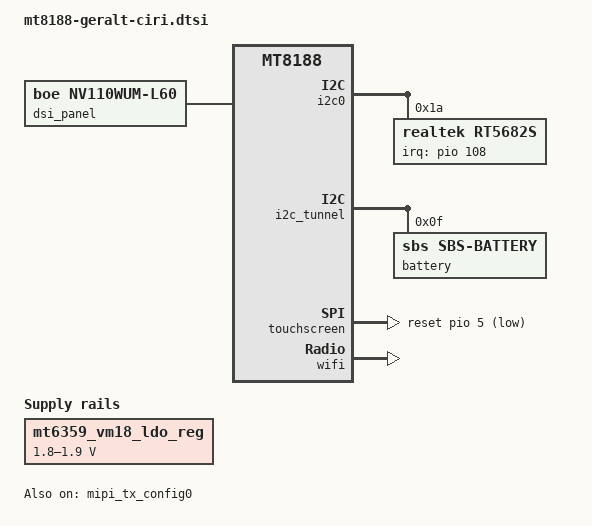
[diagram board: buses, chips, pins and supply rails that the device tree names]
// SPDX-License-Identifier: (GPL-2.0 OR MIT)
/*
 * Copyright 2023 Google LLC
 */
/dts-v1/;
#include "mt8188-geralt.dtsi"

/delete-node/ &dp_intf0;
/delete-node/ &edp_panel;
/delete-node/ &edp_tx;
/delete-node/ &max98390_3a;
/delete-node/ &max98390_3b;
/delete-node/ &nau8825;
/delete-node/ &pp3300_edp_disp;

&aud_etdm_spk_on {
	pins-bus {
		drive-strength = <MTK_DRIVE_8mA>;
	};
};

&dsi_panel {
	compatible = "boe,nv110wum-l60";
};

&disp_pwm1 {
	status = "disabled";
};

&dmic_codec {
	wakeup-delay-ms = <100>;
};

&i2c0 {
	rt5682s: rt5682s@1a {
		compatible = "realtek,rt5682s";
		reg = <0x1a>;
		interrupt-parent = <&pio>;
		interrupts = <108 IRQ_TYPE_EDGE_BOTH>;
		realtek,jd-src = <1>;
		#sound-dai-cells = <0>;
		status = "okay";
	};
};

&max98390_38 {
	sound-name-prefix = "Front Right";
	maxim,dsm_param_name = "dsm_param.bin";
};

&max98390_39 {
	sound-name-prefix = "Front Left";
	maxim,dsm_param_name = "dsm_param.bin";
};

&mipi_tx_config0 {
	drive-strength-microamp = <5200>;
	status = "okay";
};

&mt6359_vm18_ldo_reg {
	regulator-min-microvolt = <1800000>;
	regulator-microvolt-offset = <100000>;
	regulator-max-microvolt = <1900000>;
};

&i2c_tunnel {
	/delete-node/ sbs-battery@b;

	battery: sbs-battery@f {
		compatible = "sbs,sbs-battery";
		reg = <0xf>;
		sbs,i2c-retry-count = <2>;
		sbs,poll-retry-count = <1>;
	};
};

&i2c2 {
	status = "disabled";
};

&mmc1 {
	status = "disabled";
};

&ap_sar_sensor {
	status = "disabled";
};

&sound {
	compatible = "mediatek,mt8188-rt5682s";
	model = "mt8188_m98390_5682";

	audio-routing =
		"ETDM1_OUT", "ETDM_SPK_PIN",
		"ETDM2_OUT", "ETDM_HP_PIN",
		"ETDM1_IN", "ETDM_SPK_PIN",
		"ETDM2_IN", "ETDM_HP_PIN",
		"ADDA Capture", "MTKAIF_PIN",
		"Headphone Jack", "HPOL",
		"Headphone Jack", "HPOR",
		"IN1P", "Headset Mic",
		"Left Spk", "Front Left BE_OUT",
		"Right Spk", "Front Right BE_OUT";
	status = "okay";

	dai-link-0 {
		link-name = "ETDM2_OUT_BE";
		mediatek,clk-provider = "cpu";

		codec {
			sound-dai = <&rt5682s>;
		};
	};

	dai-link-1 {
		link-name = "ETDM2_IN_BE";
		mediatek,clk-provider = "cpu";

		codec {
			sound-dai = <&rt5682s>;
		};
	};

	dai-link-2 {
		link-name = "ETDM1_OUT_BE";
		dai-format = "i2s";
		mediatek,clk-provider = "cpu";

		codec {
			sound-dai = <&max98390_38>,
				    <&max98390_39>;
		};
	};

	dai-link-3 {
		link-name = "ETDM1_IN_BE";
		dai-format = "i2s";
		mediatek,clk-provider = "cpu";
	};
};

&spi1 {
	#address-cells = <1>;
	#size-cells = <0>;
	num-cs = <1>;
	pinctrl-names = "default", "sleep";
	pinctrl-0 = <&spi1_default>;
	pinctrl-1 = <&spi1_sleep>;

	touchscreen: hid-hx-common-spi@0 {
		compatible = "himax,hx83102j";
		reg = <0>;
		firmware-name = "himax_i2chid_1002.bin";
		interrupt-parent = <&pio>;
		interrupts = <143 IRQ_TYPE_LEVEL_LOW>;
		irq_flag = <0x02>;
		panel = <&dsi_panel>;
		pinctrl-names = "default";
		pinctrl-0 = <&tchscr_int &tchscr_rst>;
		reset-gpios = <&pio 5 GPIO_ACTIVE_LOW>;
		spi-max-frequency = <12500000>;
		himax_gpio_irq = <&pio 143 IRQ_TYPE_LEVEL_LOW>;
		himax,pid = <0x1002>;
		status = "okay";
	};
};

&thermal_zones {
	soc_max {
		trips {
			target: target@1 {
				temperature = <90000>;
				hysteresis = <2000>;
				type = "passive";
			};
		};
	};
};

&aud_etdm_hp_on {
	pins-mclk {
		pinmux = <PINMUX_GPIO114__FUNC_O_I2SO2_MCK>;
	};
};

&aud_etdm_hp_off {
	pins-mclk {
		pinmux = <PINMUX_GPIO114__FUNC_B_GPIO114>;
		bias-pull-down;
		input-enable;
	};
};

&pio {
	gpio-line-names =
		"GSC_AP_INT_ODL",
		"AP_DISP_BKLTEN",
		"",
		"EN_PPVAR_MIPI_DISP",
		"EN_PPVAR_MIPI_DISP_150MA",
		"TCHSCR_RST_1V8_L",
		"",
		"",
		"",
		"",
		"",
		"I2S_SPKR_DATAOUT",
		"EN_PP3300_WLAN_X",
		"WIFI_KILL_1V8_L",
		"BT_KILL_1V8_L",
		"AP_FLASH_WP_L", /* ... is crossystem ABI. Rev1 schematics call it AP_WP_ODL. */
		"",
		"",
		"WCAM_PWDN_L",
		"WCAM_RST_L",
		"UCAM_PWDM_L",
		"UCAM_RST_L",
		"WCAM_24M_CLK",
		"UCAM_24M_CLK",
		"MT6319_INT",
		"DISP_RST_1V8_L",
		"DSIO_DSI_TE",
		"",
		"TP",
		"MIPI_BL_PWM_1V8",
		"",
		"UART_AP_TX_GSC_RX",
		"UART_GSC_TX_AP_RX",
		"UART_SSPM_TX_DBGCON_RX",
		"UART_DBGCON_TX_SSPM_RX",
		"UART_ADSP_TX_DBGCON_RX",
		"UART_DBGCON_TX_ADSP_RX",
		"JTAG_AP_TMS",
		"JTAG_AP_TCK",
		"JTAG_AP_TDI",
		"JTAG_AP_TDO",
		"JTAG_AP_TRST",
		"AP_KPCOL0",
		"TP",
		"",
		"TP",
		"EC_AP_HPD_OD",
		"PCIE_WAKE_1V8_ODL",
		"PCIE_RST_1V8_L",
		"PCIE_CLKREQ_1V8_ODL",
		"",
		"",
		"",
		"",
		"",
		"AP_I2C_AUD_SCL_1V8",
		"AP_I2C_AUD_SDA_1V8",
		"AP_I2C_TPM_SCL_1V8",
		"AP_I2C_TPM_SDA_1V8",
		"AP_I2C_TCHSCR_SCL_1V8",
		"AP_I2C_TCHSCR_SDA_1V8",
		"AP_I2C_PMIC_SAR_SCL_1V8",
		"AP_I2C_PMIC_SAR_SDA_1V8",
		"AP_I2C_EC_HID_KB_SCL_1V8",
		"AP_I2C_EC_HID_KB_SDA_1V8",
		"AP_I2C_UCAM_SCL_1V8",
		"AP_I2C_UCAM_SDA_1V8",
		"AP_I2C_WCAM_SCL_1V8",
		"AP_I2C_WCAM_SDA_1V8",
		"SPI_AP_CS_EC_L",
		"SPI_AP_CLK_EC",
		"SPI_AP_DO_EC_DI",
		"SPI_AP_DI_EC_DO",
		"TP",
		"TP",
		"SPI_AP_CS_TCHSCR_L",
		"SPI_AP_CLK_TCHSCR",
		"SPI_AP_DO_TCHSCR_DI",
		"SPI_AP_DI_TCHSCR_DO",
		"TP",
		"TP",
		"TP",
		"TP",
		"",
		"",
		"",
		"TP",
		"",
		"",
		"",
		"",
		"",
		"PWRAP_SPI_CS_L",
		"PWRAP_SPI_CK",
		"PWRAP_SPI_MOSI",
		"PWRAP_SPI_MISO",
		"SRCLKENA0",
		"SRCLKENA1",
		"SCP_VREQ_VAO",
		"AP_RTC_CLK32K",
		"AP_PMIC_WDTRST_L",
		"AUD_CLK_MOSI",
		"AUD_SYNC_MOSI",
		"AUD_DAT_MOSI0",
		"AUD_DAT_MOSI1",
		"AUD_DAT_MISO0",
		"AUD_DAT_MISO1",
		"",
		"HP_INT_ODL",
		"SPKR_INT_ODL",
		"I2S_HP_DATAIN",
		"EN_SPKR",
		"I2S_SPKR_MCLK",
		"I2S_SPKR_BCLK",
		"I2S_HP_MCLK",
		"I2S_HP_BCLK",
		"I2S_HP_LRCK",
		"I2S_HP_DATAOUT",
		"RST_SPKR_L",
		"I2S_SPKR_LRCK",
		"I2S_SPKR_DATAIN",
		"",
		"",
		"",
		"",
		"SPI_AP_CLK_ROM",
		"SPI_AP_CS_ROM_L",
		"SPI_AP_DO_ROM_DI",
		"SPI_AP_DI_ROM_DO",
		"TP",
		"TP",
		"",
		"",
		"",
		"",
		"",
		"",
		"",
		"",
		"EN_PP2800A_UCAM_X",
		"EN_PP1200_UCAM_X",
		"EN_PP2800A_WCAM_X",
		"EN_PP1100_WCAM_X",
		"TCHSCR_INT_1V8_L",
		"",
		"MT7921_PMU_EN_1V8",
		"",
		"AP_EC_WARM_RST_REQ",
		"EC_AP_HID_INT_ODL",
		"EC_AP_INT_ODL",
		"AP_XHCI_INIT_DONE",
		"EMMC_DAT7",
		"EMMC_DAT6",
		"EMMC_DAT5",
		"EMMC_DAT4",
		"EMMC_RST_L",
		"EMMC_CMD",
		"EMMC_CLK",
		"EMMC_DAT3",
		"EMMC_DAT2",
		"EMMC_DAT1",
		"EMMC_DAT0",
		"EMMC_DSL",
		"",
		"",
		"",
		"",
		"",
		"",
		"",
		"",
		"USB3_HUB_RST_L",
		"EC_AP_RSVD0_ODL",
		"",
		"",
		"SPMI_SCL",
		"SPMI_SDA";

	tchscr_rst: touch-reset-pins {
		pins-tchscr-rst {
			pinmux = <PINMUX_GPIO5__FUNC_B_GPIO5>;
			output-high;
		};
	};

	spi1_default: spi1-default-pins {
		pins-bus {
			pinmux = <PINMUX_GPIO75__FUNC_O_SPIM1_CSB>,
				 <PINMUX_GPIO76__FUNC_O_SPIM1_CLK>,
				 <PINMUX_GPIO77__FUNC_B0_SPIM1_MOSI>,
				 <PINMUX_GPIO78__FUNC_B0_SPIM1_MISO>;
			bias-disable;
			drive-strength = <MTK_DRIVE_10mA>;
		};
	};

	spi1_sleep: spi1-sleep-pins {
		pins-bus {
			pinmux = <PINMUX_GPIO75__FUNC_B_GPIO75>,
				 <PINMUX_GPIO76__FUNC_B_GPIO76>,
				 <PINMUX_GPIO77__FUNC_B_GPIO77>,
				 <PINMUX_GPIO78__FUNC_B_GPIO78>;
			bias-pull-down;
			input-enable;
		};
	};
};

&wifi {
	power-limits {
		r0{
			regdomain="fcc";
			txpower-2g {
					b0 {
						channels = <1 1>;
						txs-delta = <0 0 0>;
						rates-cck = <35 35 35 35>;
						rates-ofdm = <31 31 31 31 31 31 31 31>;
						rates-mcs =
						<1 30 30 30 30 30 30 30 30 30 30>,
						<1 27 27 27 27 27 27 27 27 27 27>,
						<1 127 127 127 127 127 127 127 127 127 127>,
						<1 127 127 127 127 127 127 127 127 127 127>;
						rates-ru =
						<1 11 11 11 11 11 11 11 11 11 11 11 11>,
						<1 17 17 17 17 17 17 17 17 17 17 17 17>,
						<1 24 24 24 24 24 24 24 24 24 24 24 24>,
						<1 31 31 31 31 31 31 31 31 31 31 31 31>,
						<1 27 27 27 27 27 27 27 27 27 27 27 27>,
						<1 127 127 127 127 127 127 127 127 127 127 127 127>,
						<1 127 127 127 127 127 127 127 127 127 127 127 127>;
					};
					b1 {
						channels = <2 2>;
						txs-delta = <0 0 0>;
						rates-cck = <35 35 35 35>;
						rates-ofdm = <33 33 33 33 33 33 33 33>;
						rates-mcs =
						<1 32 32 32 32 32 32 32 32 32 32>,
						<1 27 27 27 27 27 27 27 27 27 27>,
						<1 127 127 127 127 127 127 127 127 127 127>,
						<1 127 127 127 127 127 127 127 127 127 127>;
						rates-ru =
						<1 12 12 12 12 12 12 12 12 12 12 12 12>,
						<1 18 18 18 18 18 18 18 18 18 18 18 18>,
						<1 25 25 25 25 25 25 25 25 25 25 25 25>,
						<1 32 32 32 32 32 32 32 32 32 32 32 32>,
						<1 27 27 27 27 27 27 27 27 27 27 27 27>,
						<1 127 127 127 127 127 127 127 127 127 127 127 127>,
						<1 127 127 127 127 127 127 127 127 127 127 127 127>;
					};
					b2 {
						channels = <3 3>;
						txs-delta = <0 0 0>;
						rates-cck = <35 35 35 35>;
						rates-ofdm = <34 34 34 34 34 34 34 34>;
						rates-mcs =
						<1 32 32 32 32 32 32 32 32 32 32>,
						<1 27 27 27 27 27 27 27 27 27 27>,
						<1 127 127 127 127 127 127 127 127 127 127>,
						<1 127 127 127 127 127 127 127 127 127 127>;
						rates-ru =
						<1 12 12 12 12 12 12 12 12 12 12 12 12>,
						<1 18 18 18 18 18 18 18 18 18 18 18 18>,
						<1 25 25 25 25 25 25 25 25 25 25 25 25>,
						<1 32 32 32 32 32 32 32 32 32 32 32 32>,
						<1 27 27 27 27 27 27 27 27 27 27 27 27>,
						<1 127 127 127 127 127 127 127 127 127 127 127 127>,
						<1 127 127 127 127 127 127 127 127 127 127 127 127>;
					};
					b3 {
						channels = <4 4>;
						txs-delta = <0 0 0>;
						rates-cck = <35 35 35 35>;
						rates-ofdm = <34 34 34 34 34 34 34 34>;
						rates-mcs =
						<1 33 33 33 33 33 33 33 33 33 33>,
						<1 28 28 28 28 28 28 28 28 28 28>,
						<1 127 127 127 127 127 127 127 127 127 127>,
						<1 127 127 127 127 127 127 127 127 127 127>;
						rates-ru =
						<1 13 13 13 13 13 13 13 13 13 13 13 13>,
						<1 19 19 19 19 19 19 19 19 19 19 19 19>,
						<1 26 26 26 26 26 26 26 26 26 26 26 26>,
						<1 33 33 33 33 33 33 33 33 33 33 33 33>,
						<1 28 28 28 28 28 28 28 28 28 28 28 28>,
						<1 127 127 127 127 127 127 127 127 127 127 127 127>,
						<1 127 127 127 127 127 127 127 127 127 127 127 127>;
					};
					b4 {
						channels = <5 5>;
						txs-delta = <0 0 0>;
						rates-cck = <35 35 35 35>;
						rates-ofdm = <34 34 34 34 34 34 34 34>;
						rates-mcs =
						<1 33 33 33 33 33 33 33 33 33 33>,
						<1 28 28 28 28 28 28 28 28 28 28>,
						<1 127 127 127 127 127 127 127 127 127 127>,
						<1 127 127 127 127 127 127 127 127 127 127>;
						rates-ru =
						<1 13 13 13 13 13 13 13 13 13 13 13 13>,
						<1 19 19 19 19 19 19 19 19 19 19 19 19>,
						<1 26 26 26 26 26 26 26 26 26 26 26 26>,
						<1 33 33 33 33 33 33 33 33 33 33 33 33>,
						<1 28 28 28 28 28 28 28 28 28 28 28 28>,
						<1 127 127 127 127 127 127 127 127 127 127 127 127>,
						<1 127 127 127 127 127 127 127 127 127 127 127 127>;
					};
					b5 {
						channels = <6 6>;
						txs-delta = <0 0 0>;
						rates-cck = <35 35 35 35>;
						rates-ofdm = <34 34 34 34 34 34 34 34>;
						rates-mcs =
						<1 33 33 33 33 33 33 33 33 33 33>,
						<1 29 29 29 29 29 29 29 29 29 29>,
						<1 127 127 127 127 127 127 127 127 127 127>,
						<1 127 127 127 127 127 127 127 127 127 127>;
						rates-ru =
						<1 13 13 13 13 13 13 13 13 13 13 13 13>,
						<1 19 19 19 19 19 19 19 19 19 19 19 19>,
						<1 26 26 26 26 26 26 26 26 26 26 26 26>,
						<1 33 33 33 33 33 33 33 33 33 33 33 33>,
						<1 29 29 29 29 29 29 29 29 29 29 29 29>,
						<1 127 127 127 127 127 127 127 127 127 127 127 127>,
						<1 127 127 127 127 127 127 127 127 127 127 127 127>;
					};
					b6 {
						channels = <7 7>;
						txs-delta = <0 0 0>;
						rates-cck = <35 35 35 35>;
						rates-ofdm = <34 34 34 34 34 34 34 34>;
						rates-mcs =
						<1 33 33 33 33 33 33 33 33 33 33>,
						<1 28 28 28 28 28 28 28 28 28 28>,
						<1 127 127 127 127 127 127 127 127 127 127>,
						<1 127 127 127 127 127 127 127 127 127 127>;
						rates-ru =
						<1 13 13 13 13 13 13 13 13 13 13 13 13>,
						<1 19 19 19 19 19 19 19 19 19 19 19 19>,
						<1 26 26 26 26 26 26 26 26 26 26 26 26>,
						<1 33 33 33 33 33 33 33 33 33 33 33 33>,
						<1 28 28 28 28 28 28 28 28 28 28 28 28>,
						<1 127 127 127 127 127 127 127 127 127 127 127 127>,
						<1 127 127 127 127 127 127 127 127 127 127 127 127>;
					};
					b7 {
						channels = <8 8>;
						txs-delta = <0 0 0>;
						rates-cck = <35 35 35 35>;
						rates-ofdm = <34 34 34 34 34 34 34 34>;
						rates-mcs =
						<1 33 33 33 33 33 33 33 33 33 33>,
						<1 28 28 28 28 28 28 28 28 28 28>,
						<1 127 127 127 127 127 127 127 127 127 127>,
						<1 127 127 127 127 127 127 127 127 127 127>;
						rates-ru =
						<1 13 13 13 13 13 13 13 13 13 13 13 13>,
						<1 19 19 19 19 19 19 19 19 19 19 19 19>,
						<1 26 26 26 26 26 26 26 26 26 26 26 26>,
						<1 33 33 33 33 33 33 33 33 33 33 33 33>,
						<1 28 28 28 28 28 28 28 28 28 28 28 28>,
						<1 127 127 127 127 127 127 127 127 127 127 127 127>,
						<1 127 127 127 127 127 127 127 127 127 127 127 127>;
					};
					b8 {
						channels = <9 9>;
						txs-delta = <0 0 0>;
						rates-cck = <35 35 35 35>;
						rates-ofdm = <34 34 34 34 34 34 34 34>;
						rates-mcs =
						<1 32 32 32 32 32 32 32 32 32 32>,
						<1 27 27 27 27 27 27 27 27 27 27>,
						<1 127 127 127 127 127 127 127 127 127 127>,
						<1 127 127 127 127 127 127 127 127 127 127>;
						rates-ru =
						<1 12 12 12 12 12 12 12 12 12 12 12 12>,
						<1 18 18 18 18 18 18 18 18 18 18 18 18>,
						<1 25 25 25 25 25 25 25 25 25 25 25 25>,
						<1 32 32 32 32 32 32 32 32 32 32 32 32>,
						<1 27 27 27 27 27 27 27 27 27 27 27 27>,
						<1 127 127 127 127 127 127 127 127 127 127 127 127>,
						<1 127 127 127 127 127 127 127 127 127 127 127 127>;
					};
					b9 {
						channels = <10 10>;
						txs-delta = <0 0 0>;
						rates-cck = <35 35 35 35>;
						rates-ofdm = <33 33 33 33 33 33 33 33>;
						rates-mcs =
						<1 32 32 32 32 32 32 32 32 32 32>,
						<1 14 14 14 14 14 14 14 14 14 14>,
						<1 127 127 127 127 127 127 127 127 127 127>,
						<1 127 127 127 127 127 127 127 127 127 127>;
						rates-ru =
						<1 12 12 12 12 12 12 12 12 12 12 12 12>,
						<1 18 18 18 18 18 18 18 18 18 18 18 18>,
						<1 25 25 25 25 25 25 25 25 25 25 25 25>,
						<1 32 32 32 32 32 32 32 32 32 32 32 32>,
						<1 14 14 14 14 14 14 14 14 14 14 14 14>,
						<1 127 127 127 127 127 127 127 127 127 127 127 127>,
						<1 127 127 127 127 127 127 127 127 127 127 127 127>;
					};
					b10 {
						channels = <11 11>;
						txs-delta = <0 0 0>;
						rates-cck = <35 35 35 35>;
						rates-ofdm = <31 31 31 31 31 31 31 31>;
						rates-mcs =
						<1 30 30 30 30 30 30 30 30 30 30>,
						<1 2 2 2 2 2 2 2 2 2 2>,
						<1 127 127 127 127 127 127 127 127 127 127>,
						<1 127 127 127 127 127 127 127 127 127 127>;
						rates-ru =
						<1 10 10 10 10 10 10 10 10 10 10 10 10>,
						<1 16 16 16 16 16 16 16 16 16 16 16 16>,
						<1 23 23 23 23 23 23 23 23 23 23 23 23>,
						<1 30 30 30 30 30 30 30 30 30 30 30 30>,
						<1 2 2 2 2 2 2 2 2 2 2 2 2>,
						<1 127 127 127 127 127 127 127 127 127 127 127 127>,
						<1 127 127 127 127 127 127 127 127 127 127 127 127>;
					};
					b11 {
						channels = <12 12>;
						txs-delta = <0 0 0>;
						rates-cck = <28 28 28 28>;
						rates-ofdm = <21 21 21 21 21 21 21 21>;
						rates-mcs =
						<1 17 17 17 17 17 17 17 17 17 17>,
						<1 10 10 10 10 10 10 10 10 10 10>,
						<1 127 127 127 127 127 127 127 127 127 127>,
						<1 127 127 127 127 127 127 127 127 127 127>;
						rates-ru =
						<1 (-2) (-2) (-2) (-2) (-2) (-2) (-2) (-2) (-2) (-2) (-2) (-2)>,
						<1 4 4 4 4 4 4 4 4 4 4 4 4>,
						<1 11 11 11 11 11 11 11 11 11 11 11 11>,
						<1 18 18 18 18 18 18 18 18 18 18 18 18>,
						<1 10 10 10 10 10 10 10 10 10 10 10 10>,
						<1 127 127 127 127 127 127 127 127 127 127 127 127>,
						<1 127 127 127 127 127 127 127 127 127 127 127 127>;
					};
					b12 {
						channels = <13 13>;
						txs-delta = <0 0 0>;
						rates-cck = <15 15 15 15>;
						rates-ofdm = <11 11 11 11 11 11 11 11>;
						rates-mcs =
						<1 8 8 8 8 8 8 8 8 8 8>,
						<1 10 10 10 10 10 10 10 10 10 10>,
						<1 127 127 127 127 127 127 127 127 127 127>,
						<1 127 127 127 127 127 127 127 127 127 127>;
						rates-ru =
						<1 (-11) (-11) (-11) (-11) (-11) (-11) (-11) (-11) (-11) (-11) (-11) (-11)>,
						<1 (-5) (-5) (-5) (-5) (-5) (-5) (-5) (-5) (-5) (-5) (-5) (-5)>,
						<1 2 2 2 2 2 2 2 2 2 2 2 2>,
						<1 9 9 9 9 9 9 9 9 9 9 9 9>,
						<1 10 10 10 10 10 10 10 10 10 10 10 10>,
						<1 127 127 127 127 127 127 127 127 127 127 127 127>,
						<1 127 127 127 127 127 127 127 127 127 127 127 127>;
					};
					b13 {
						channels = <14 14>;
						txs-delta = <0 0 0>;
						rates-cck = <15 15 15 15>;
						rates-ofdm = <11 11 11 11 11 11 11 11>;
						rates-mcs =
						<1 8 8 8 8 8 8 8 8 8 8>,
						<1 10 10 10 10 10 10 10 10 10 10>,
						<1 127 127 127 127 127 127 127 127 127 127>,
						<1 127 127 127 127 127 127 127 127 127 127>;
						rates-ru =
						<1 (-11) (-11) (-11) (-11) (-11) (-11) (-11) (-11) (-11) (-11) (-11) (-11)>,
						<1 (-5) (-5) (-5) (-5) (-5) (-5) (-5) (-5) (-5) (-5) (-5) (-5)>,
						<1 2 2 2 2 2 2 2 2 2 2 2 2>,
						<1 9 9 9 9 9 9 9 9 9 9 9 9>,
						<1 10 10 10 10 10 10 10 10 10 10 10 10>,
						<1 127 127 127 127 127 127 127 127 127 127 127 127>,
						<1 127 127 127 127 127 127 127 127 127 127 127 127>;
					};
			};
			txpower-5g {
					b0 {
						channels = <36 36>;
						txs-delta = <0 0 0>;
						rates-ofdm = <28 28 28 28 28 28 28 28>;
						rates-mcs =
						<1 28 28 28 28 28 28 28 28 28 28>,
						<1 27 27 27 27 27 27 27 27 27 27>,
						<1 25 25 25 25 25 25 25 25 25 25>,
						<1 127 127 127 127 127 127 127 127 127 127>;
						rates-ru =
						<1 9 9 9 9 9 9 9 9 9 9 9 9>,
						<1 15 15 15 15 15 15 15 15 15 15 15 15>,
						<1 22 22 22 22 22 22 22 22 22 22 22 22>,
						<1 29 29 29 29 29 29 29 29 29 29 29 29>,
						<1 127 127 127 127 127 127 127 127 127 127 127 127>,
						<1 127 127 127 127 127 127 127 127 127 127 127 127>,
						<1 127 127 127 127 127 127 127 127 127 127 127 127>;
					};
					b1 {
						channels = <38 38>;
						txs-delta = <0 0 0>;
						rates-ofdm = <28 28 28 28 28 28 28 28>;
						rates-mcs =
						<1 28 28 28 28 28 28 28 28 28 28>,
						<1 27 27 27 27 27 27 27 27 27 27>,
						<1 25 25 25 25 25 25 25 25 25 25>,
						<1 127 127 127 127 127 127 127 127 127 127>;
						rates-ru =
						<1 9 9 9 9 9 9 9 9 9 9 9 9>,
						<1 15 15 15 15 15 15 15 15 15 15 15 15>,
						<1 22 22 22 22 22 22 22 22 22 22 22 22>,
						<1 29 29 29 29 29 29 29 29 29 29 29 29>,
						<1 27 27 27 27 27 27 27 27 27 27 27 27>,
						<1 127 127 127 127 127 127 127 127 127 127 127 127>,
						<1 127 127 127 127 127 127 127 127 127 127 127 127>;
					};
					b2 {
						channels = <40 40>;
						txs-delta = <0 0 0>;
						rates-ofdm = <31 31 31 31 31 31 31 31>;
						rates-mcs =
						<1 31 31 31 31 31 31 31 31 31 31>,
						<1 27 27 27 27 27 27 27 27 27 27>,
						<1 25 25 25 25 25 25 25 25 25 25>,
						<1 127 127 127 127 127 127 127 127 127 127>;
						rates-ru =
						<1 11 11 11 11 11 11 11 11 11 11 11 11>,
						<1 17 17 17 17 17 17 17 17 17 17 17 17>,
						<1 24 24 24 24 24 24 24 24 24 24 24 24>,
						<1 31 31 31 31 31 31 31 31 31 31 31 31>,
						<1 127 127 127 127 127 127 127 127 127 127 127 127>,
						<1 127 127 127 127 127 127 127 127 127 127 127 127>,
						<1 127 127 127 127 127 127 127 127 127 127 127 127>;
					};
					b3 {
						channels = <42 42>;
						txs-delta = <0 0 0>;
						rates-ofdm = <31 31 31 31 31 31 31 31>;
						rates-mcs =
						<1 31 31 31 31 31 31 31 31 31 31>,
						<1 27 27 27 27 27 27 27 27 27 27>,
						<1 25 25 25 25 25 25 25 25 25 25>,
						<1 127 127 127 127 127 127 127 127 127 127>;
						rates-ru =
						<1 11 11 11 11 11 11 11 11 11 11 11 11>,
						<1 17 17 17 17 17 17 17 17 17 17 17 17>,
						<1 24 24 24 24 24 24 24 24 24 24 24 24>,
						<1 31 31 31 31 31 31 31 31 31 31 31 31>,
						<1 27 27 27 27 27 27 27 27 27 27 27 27>,
						<1 25 25 25 25 25 25 25 25 25 25 25 25>,
						<1 127 127 127 127 127 127 127 127 127 127 127 127>;
					};
					b4 {
						channels = <44 44>;
						txs-delta = <0 0 0>;
						rates-ofdm = <33 33 33 33 33 33 33 33>;
						rates-mcs =
						<1 32 32 32 32 32 32 32 32 32 32>,
						<1 32 32 32 32 32 32 32 32 32 32>,
						<1 25 25 25 25 25 25 25 25 25 25>,
						<1 127 127 127 127 127 127 127 127 127 127>;
						rates-ru =
						<1 12 12 12 12 12 12 12 12 12 12 12 12>,
						<1 18 18 18 18 18 18 18 18 18 18 18 18>,
						<1 25 25 25 25 25 25 25 25 25 25 25 25>,
						<1 32 32 32 32 32 32 32 32 32 32 32 32>,
						<1 127 127 127 127 127 127 127 127 127 127 127 127>,
						<1 127 127 127 127 127 127 127 127 127 127 127 127>,
						<1 127 127 127 127 127 127 127 127 127 127 127 127>;
					};
					b5 {
						channels = <46 46>;
						txs-delta = <0 0 0>;
						rates-ofdm = <33 33 33 33 33 33 33 33>;
						rates-mcs =
						<1 32 32 32 32 32 32 32 32 32 32>,
						<1 32 32 32 32 32 32 32 32 32 32>,
						<1 25 25 25 25 25 25 25 25 25 25>,
						<1 127 127 127 127 127 127 127 127 127 127>;
						rates-ru =
						<1 12 12 12 12 12 12 12 12 12 12 12 12>,
						<1 18 18 18 18 18 18 18 18 18 18 18 18>,
						<1 25 25 25 25 25 25 25 25 25 25 25 25>,
						<1 32 32 32 32 32 32 32 32 32 32 32 32>,
						<1 32 32 32 32 32 32 32 32 32 32 32 32>,
						<1 127 127 127 127 127 127 127 127 127 127 127 127>,
						<1 127 127 127 127 127 127 127 127 127 127 127 127>;
					};
					b6 {
						channels = <48 48>;
						txs-delta = <0 0 0>;
						rates-ofdm = <34 34 34 34 34 34 34 34>;
						rates-mcs =
						<1 33 33 33 33 33 33 33 33 33 33>,
						<1 32 32 32 32 32 32 32 32 32 32>,
						<1 25 25 25 25 25 25 25 25 25 25>,
						<1 127 127 127 127 127 127 127 127 127 127>;
						rates-ru =
						<1 13 13 13 13 13 13 13 13 13 13 13 13>,
						<1 19 19 19 19 19 19 19 19 19 19 19 19>,
						<1 26 26 26 26 26 26 26 26 26 26 26 26>,
						<1 33 33 33 33 33 33 33 33 33 33 33 33>,
						<1 127 127 127 127 127 127 127 127 127 127 127 127>,
						<1 127 127 127 127 127 127 127 127 127 127 127 127>,
						<1 127 127 127 127 127 127 127 127 127 127 127 127>;
					};
					b7 {
						channels = <50 50>;
						txs-delta = <0 0 0>;
						rates-ofdm = <34 34 34 34 34 34 34 34>;
						rates-mcs =
						<1 34 34 34 34 34 34 34 34 34 34>,
						<1 32 32 32 32 32 32 32 32 32 32>,
						<1 25 25 25 25 25 25 25 25 25 25>,
						<1 127 127 127 127 127 127 127 127 127 127>;
						rates-ru =
						<1 14 14 14 14 14 14 14 14 14 14 14 14>,
						<1 20 20 20 20 20 20 20 20 20 20 20 20>,
						<1 27 27 27 27 27 27 27 27 27 27 27 27>,
						<1 34 34 34 34 34 34 34 34 34 34 34 34>,
						<1 32 32 32 32 32 32 32 32 32 32 32 32>,
						<1 25 25 25 25 25 25 25 25 25 25 25 25>,
						<1 127 127 127 127 127 127 127 127 127 127 127 127>;
					};
					b8 {
						channels = <52 52>;
						txs-delta = <0 0 0>;
						rates-ofdm = <34 34 34 34 34 34 34 34>;
						rates-mcs =
						<1 34 34 34 34 34 34 34 34 34 34>,
						<1 32 32 32 32 32 32 32 32 32 32>,
						<1 25 25 25 25 25 25 25 25 25 25>,
						<1 127 127 127 127 127 127 127 127 127 127>;
						rates-ru =
						<1 14 14 14 14 14 14 14 14 14 14 14 14>,
						<1 20 20 20 20 20 20 20 20 20 20 20 20>,
						<1 27 27 27 27 27 27 27 27 27 27 27 27>,
						<1 34 34 34 34 34 34 34 34 34 34 34 34>,
						<1 127 127 127 127 127 127 127 127 127 127 127 127>,
						<1 127 127 127 127 127 127 127 127 127 127 127 127>,
						<1 127 127 127 127 127 127 127 127 127 127 127 127>;
					};
					b9 {
						channels = <54 54>;
						txs-delta = <0 0 0>;
						rates-ofdm = <34 34 34 34 34 34 34 34>;
						rates-mcs =
						<1 34 34 34 34 34 34 34 34 34 34>,
						<1 32 32 32 32 32 32 32 32 32 32>,
						<1 25 25 25 25 25 25 25 25 25 25>,
						<1 127 127 127 127 127 127 127 127 127 127>;
						rates-ru =
						<1 14 14 14 14 14 14 14 14 14 14 14 14>,
						<1 20 20 20 20 20 20 20 20 20 20 20 20>,
						<1 27 27 27 27 27 27 27 27 27 27 27 27>,
						<1 34 34 34 34 34 34 34 34 34 34 34 34>,
						<1 32 32 32 32 32 32 32 32 32 32 32 32>,
						<1 127 127 127 127 127 127 127 127 127 127 127 127>,
						<1 127 127 127 127 127 127 127 127 127 127 127 127>;
					};
					b10 {
						channels = <56 56>;
						txs-delta = <0 0 0>;
						rates-ofdm = <34 34 34 34 34 34 34 34>;
						rates-mcs =
						<1 34 34 34 34 34 34 34 34 34 34>,
						<1 32 32 32 32 32 32 32 32 32 32>,
						<1 25 25 25 25 25 25 25 25 25 25>,
						<1 127 127 127 127 127 127 127 127 127 127>;
						rates-ru =
						<1 13 13 13 13 13 13 13 13 13 13 13 13>,
						<1 19 19 19 19 19 19 19 19 19 19 19 19>,
						<1 26 26 26 26 26 26 26 26 26 26 26 26>,
						<1 33 33 33 33 33 33 33 33 33 33 33 33>,
						<1 127 127 127 127 127 127 127 127 127 127 127 127>,
						<1 127 127 127 127 127 127 127 127 127 127 127 127>,
						<1 127 127 127 127 127 127 127 127 127 127 127 127>;
					};
					b11 {
						channels = <58 58>;
						txs-delta = <0 0 0>;
						rates-ofdm = <34 34 34 34 34 34 34 34>;
						rates-mcs =
						<1 33 33 33 33 33 33 33 33 33 33>,
						<1 32 32 32 32 32 32 32 32 32 32>,
						<1 25 25 25 25 25 25 25 25 25 25>,
						<1 127 127 127 127 127 127 127 127 127 127>;
						rates-ru =
						<1 13 13 13 13 13 13 13 13 13 13 13 13>,
						<1 19 19 19 19 19 19 19 19 19 19 19 19>,
						<1 26 26 26 26 26 26 26 26 26 26 26 26>,
						<1 33 33 33 33 33 33 33 33 33 33 33 33>,
						<1 32 32 32 32 32 32 32 32 32 32 32 32>,
						<1 25 25 25 25 25 25 25 25 25 25 25 25>,
						<1 127 127 127 127 127 127 127 127 127 127 127 127>;
					};
					b12 {
						channels = <60 60>;
						txs-delta = <0 0 0>;
						rates-ofdm = <34 34 34 34 34 34 34 34>;
						rates-mcs =
						<1 32 32 32 32 32 32 32 32 32 32>,
						<1 27 27 27 27 27 27 27 27 27 27>,
						<1 25 25 25 25 25 25 25 25 25 25>,
						<1 127 127 127 127 127 127 127 127 127 127>;
						rates-ru =
						<1 13 13 13 13 13 13 13 13 13 13 13 13>,
						<1 19 19 19 19 19 19 19 19 19 19 19 19>,
						<1 26 26 26 26 26 26 26 26 26 26 26 26>,
						<1 33 33 33 33 33 33 33 33 33 33 33 33>,
						<1 127 127 127 127 127 127 127 127 127 127 127 127>,
						<1 127 127 127 127 127 127 127 127 127 127 127 127>,
						<1 127 127 127 127 127 127 127 127 127 127 127 127>;
					};
					b13 {
						channels = <62 62>;
						txs-delta = <0 0 0>;
						rates-ofdm = <34 34 34 34 34 34 34 34>;
						rates-mcs =
						<1 32 32 32 32 32 32 32 32 32 32>,
						<1 27 27 27 27 27 27 27 27 27 27>,
						<1 25 25 25 25 25 25 25 25 25 25>,
						<1 127 127 127 127 127 127 127 127 127 127>;
						rates-ru =
						<1 13 13 13 13 13 13 13 13 13 13 13 13>,
						<1 19 19 19 19 19 19 19 19 19 19 19 19>,
						<1 26 26 26 26 26 26 26 26 26 26 26 26>,
						<1 33 33 33 33 33 33 33 33 33 33 33 33>,
						<1 27 27 27 27 27 27 27 27 27 27 27 27>,
						<1 127 127 127 127 127 127 127 127 127 127 127 127>,
						<1 127 127 127 127 127 127 127 127 127 127 127 127>;
					};
					b14 {
						channels = <64 64>;
						txs-delta = <0 0 0>;
						rates-ofdm = <28 28 28 28 28 28 28 28>;
						rates-mcs =
						<1 28 28 28 28 28 28 28 28 28 28>,
						<1 27 27 27 27 27 27 27 27 27 27>,
						<1 25 25 25 25 25 25 25 25 25 25>,
						<1 127 127 127 127 127 127 127 127 127 127>;
						rates-ru =
						<1 8 8 8 8 8 8 8 8 8 8 8 8>,
						<1 14 14 14 14 14 14 14 14 14 14 14 14>,
						<1 21 21 21 21 21 21 21 21 21 21 21 21>,
						<1 28 28 28 28 28 28 28 28 28 28 28 28>,
						<1 127 127 127 127 127 127 127 127 127 127 127 127>,
						<1 127 127 127 127 127 127 127 127 127 127 127 127>,
						<1 127 127 127 127 127 127 127 127 127 127 127 127>;
					};
					b15 {
						channels = <100 100>;
						txs-delta = <0 0 0>;
						rates-ofdm = <30 30 30 30 30 30 30 30>;
						rates-mcs =
						<2 30 30 30 30 30 30 30 30 30 30>,
						<1 26 26 26 26 26 26 26 26 26 26>,
						<1 127 127 127 127 127 127 127 127 127 127>;
						rates-ru =
						<1 10 10 10 10 10 10 10 10 10 10 10 10>,
						<1 16 16 16 16 16 16 16 16 16 16 16 16>,
						<1 23 23 23 23 23 23 23 23 23 23 23 23>,
						<1 30 30 30 30 30 30 30 30 30 30 30 30>,
						<1 127 127 127 127 127 127 127 127 127 127 127 127>,
						<1 127 127 127 127 127 127 127 127 127 127 127 127>,
						<1 127 127 127 127 127 127 127 127 127 127 127 127>;
					};
					b16 {
						channels = <102 102>;
						txs-delta = <0 0 0>;
						rates-ofdm = <30 30 30 30 30 30 30 30>;
						rates-mcs =
						<2 30 30 30 30 30 30 30 30 30 30>,
						<1 26 26 26 26 26 26 26 26 26 26>,
						<1 127 127 127 127 127 127 127 127 127 127>;
						rates-ru =
						<1 10 10 10 10 10 10 10 10 10 10 10 10>,
						<1 16 16 16 16 16 16 16 16 16 16 16 16>,
						<1 23 23 23 23 23 23 23 23 23 23 23 23>,
						<1 30 30 30 30 30 30 30 30 30 30 30 30>,
						<1 30 30 30 30 30 30 30 30 30 30 30 30>,
						<1 127 127 127 127 127 127 127 127 127 127 127 127>,
						<1 127 127 127 127 127 127 127 127 127 127 127 127>;
					};
					b17 {
						channels = <104 104>;
						txs-delta = <0 0 0>;
						rates-ofdm = <32 32 32 32 32 32 32 32>;
						rates-mcs =
						<1 32 32 32 32 32 32 32 32 32 32>,
						<1 30 30 30 30 30 30 30 30 30 30>,
						<1 26 26 26 26 26 26 26 26 26 26>,
						<1 127 127 127 127 127 127 127 127 127 127>;
						rates-ru =
						<1 12 12 12 12 12 12 12 12 12 12 12 12>,
						<1 18 18 18 18 18 18 18 18 18 18 18 18>,
						<1 25 25 25 25 25 25 25 25 25 25 25 25>,
						<1 32 32 32 32 32 32 32 32 32 32 32 32>,
						<1 127 127 127 127 127 127 127 127 127 127 127 127>,
						<1 127 127 127 127 127 127 127 127 127 127 127 127>,
						<1 127 127 127 127 127 127 127 127 127 127 127 127>;
					};
					b18 {
						channels = <106 106>;
						txs-delta = <0 0 0>;
						rates-ofdm = <32 32 32 32 32 32 32 32>;
						rates-mcs =
						<1 32 32 32 32 32 32 32 32 32 32>,
						<1 30 30 30 30 30 30 30 30 30 30>,
						<1 26 26 26 26 26 26 26 26 26 26>,
						<1 127 127 127 127 127 127 127 127 127 127>;
						rates-ru =
						<1 12 12 12 12 12 12 12 12 12 12 12 12>,
						<1 18 18 18 18 18 18 18 18 18 18 18 18>,
						<1 25 25 25 25 25 25 25 25 25 25 25 25>,
						<1 32 32 32 32 32 32 32 32 32 32 32 32>,
						<1 30 30 30 30 30 30 30 30 30 30 30 30>,
						<1 26 26 26 26 26 26 26 26 26 26 26 26>,
						<1 127 127 127 127 127 127 127 127 127 127 127 127>;
					};
					b19 {
						channels = <108 108>;
						txs-delta = <0 0 0>;
						rates-ofdm = <34 34 34 34 34 34 34 34>;
						rates-mcs =
						<1 34 34 34 34 34 34 34 34 34 34>,
						<1 31 31 31 31 31 31 31 31 31 31>,
						<1 26 26 26 26 26 26 26 26 26 26>,
						<1 127 127 127 127 127 127 127 127 127 127>;
						rates-ru =
						<1 14 14 14 14 14 14 14 14 14 14 14 14>,
						<1 20 20 20 20 20 20 20 20 20 20 20 20>,
						<1 27 27 27 27 27 27 27 27 27 27 27 27>,
						<1 34 34 34 34 34 34 34 34 34 34 34 34>,
						<1 127 127 127 127 127 127 127 127 127 127 127 127>,
						<1 127 127 127 127 127 127 127 127 127 127 127 127>,
						<1 127 127 127 127 127 127 127 127 127 127 127 127>;
					};
					b20 {
						channels = <110 110>;
						txs-delta = <0 0 0>;
						rates-ofdm = <34 34 34 34 34 34 34 34>;
						rates-mcs =
						<1 34 34 34 34 34 34 34 34 34 34>,
						<1 31 31 31 31 31 31 31 31 31 31>,
						<1 26 26 26 26 26 26 26 26 26 26>,
						<1 127 127 127 127 127 127 127 127 127 127>;
						rates-ru =
						<1 14 14 14 14 14 14 14 14 14 14 14 14>,
						<1 20 20 20 20 20 20 20 20 20 20 20 20>,
						<1 27 27 27 27 27 27 27 27 27 27 27 27>,
						<1 34 34 34 34 34 34 34 34 34 34 34 34>,
						<1 32 32 32 32 32 32 32 32 32 32 32 32>,
						<1 127 127 127 127 127 127 127 127 127 127 127 127>,
						<1 127 127 127 127 127 127 127 127 127 127 127 127>;
					};
					b21 {
						channels = <112 112>;
						txs-delta = <0 0 0>;
						rates-ofdm = <34 34 34 34 34 34 34 34>;
						rates-mcs =
						<1 34 34 34 34 34 34 34 34 34 34>,
						<1 31 31 31 31 31 31 31 31 31 31>,
						<1 26 26 26 26 26 26 26 26 26 26>,
						<1 127 127 127 127 127 127 127 127 127 127>;
						rates-ru =
						<1 14 14 14 14 14 14 14 14 14 14 14 14>,
						<1 20 20 20 20 20 20 20 20 20 20 20 20>,
						<1 27 27 27 27 27 27 27 27 27 27 27 27>,
						<1 34 34 34 34 34 34 34 34 34 34 34 34>,
						<1 127 127 127 127 127 127 127 127 127 127 127 127>,
						<1 127 127 127 127 127 127 127 127 127 127 127 127>,
						<1 127 127 127 127 127 127 127 127 127 127 127 127>;
					};
					b22 {
						channels = <114 114>;
						txs-delta = <0 0 0>;
						rates-ofdm = <34 34 34 34 34 34 34 34>;
						rates-mcs =
						<1 34 34 34 34 34 34 34 34 34 34>,
						<1 31 31 31 31 31 31 31 31 31 31>,
						<1 26 26 26 26 26 26 26 26 26 26>,
						<1 127 127 127 127 127 127 127 127 127 127>;
						rates-ru =
						<1 14 14 14 14 14 14 14 14 14 14 14 14>,
						<1 20 20 20 20 20 20 20 20 20 20 20 20>,
						<1 27 27 27 27 27 27 27 27 27 27 27 27>,
						<1 34 34 34 34 34 34 34 34 34 34 34 34>,
						<1 32 32 32 32 32 32 32 32 32 32 32 32>,
						<1 26 26 26 26 26 26 26 26 26 26 26 26>,
						<1 127 127 127 127 127 127 127 127 127 127 127 127>;
					};
					b23 {
						channels = <116 116>;
						txs-delta = <0 0 0>;
						rates-ofdm = <34 34 34 34 34 34 34 34>;
						rates-mcs =
						<1 34 34 34 34 34 34 34 34 34 34>,
						<1 31 31 31 31 31 31 31 31 31 31>,
						<1 30 30 30 30 30 30 30 30 30 30>,
						<1 127 127 127 127 127 127 127 127 127 127>;
						rates-ru =
						<1 14 14 14 14 14 14 14 14 14 14 14 14>,
						<1 20 20 20 20 20 20 20 20 20 20 20 20>,
						<1 27 27 27 27 27 27 27 27 27 27 27 27>,
						<1 34 34 34 34 34 34 34 34 34 34 34 34>,
						<1 127 127 127 127 127 127 127 127 127 127 127 127>,
						<1 127 127 127 127 127 127 127 127 127 127 127 127>,
						<1 127 127 127 127 127 127 127 127 127 127 127 127>;
					};
					b24 {
						channels = <118 118>;
						txs-delta = <0 0 0>;
						rates-ofdm = <34 34 34 34 34 34 34 34>;
						rates-mcs =
						<1 34 34 34 34 34 34 34 34 34 34>,
						<1 31 31 31 31 31 31 31 31 31 31>,
						<1 30 30 30 30 30 30 30 30 30 30>,
						<1 127 127 127 127 127 127 127 127 127 127>;
						rates-ru =
						<1 14 14 14 14 14 14 14 14 14 14 14 14>,
						<1 20 20 20 20 20 20 20 20 20 20 20 20>,
						<1 27 27 27 27 27 27 27 27 27 27 27 27>,
						<1 34 34 34 34 34 34 34 34 34 34 34 34>,
						<1 32 32 32 32 32 32 32 32 32 32 32 32>,
						<1 127 127 127 127 127 127 127 127 127 127 127 127>,
						<1 127 127 127 127 127 127 127 127 127 127 127 127>;
					};
					b25 {
						channels = <120 120>;
						txs-delta = <0 0 0>;
						rates-ofdm = <34 34 34 34 34 34 34 34>;
						rates-mcs =
						<1 34 34 34 34 34 34 34 34 34 34>,
						<1 31 31 31 31 31 31 31 31 31 31>,
						<1 30 30 30 30 30 30 30 30 30 30>,
						<1 127 127 127 127 127 127 127 127 127 127>;
						rates-ru =
						<1 14 14 14 14 14 14 14 14 14 14 14 14>,
						<1 20 20 20 20 20 20 20 20 20 20 20 20>,
						<1 27 27 27 27 27 27 27 27 27 27 27 27>,
						<1 34 34 34 34 34 34 34 34 34 34 34 34>,
						<1 127 127 127 127 127 127 127 127 127 127 127 127>,
						<1 127 127 127 127 127 127 127 127 127 127 127 127>,
						<1 127 127 127 127 127 127 127 127 127 127 127 127>;
					};
					b26 {
						channels = <122 122>;
						txs-delta = <0 0 0>;
						rates-ofdm = <34 34 34 34 34 34 34 34>;
						rates-mcs =
						<1 34 34 34 34 34 34 34 34 34 34>,
						<1 31 31 31 31 31 31 31 31 31 31>,
						<1 30 30 30 30 30 30 30 30 30 30>,
						<1 127 127 127 127 127 127 127 127 127 127>;
						rates-ru =
						<1 14 14 14 14 14 14 14 14 14 14 14 14>,
						<1 20 20 20 20 20 20 20 20 20 20 20 20>,
						<1 27 27 27 27 27 27 27 27 27 27 27 27>,
						<1 34 34 34 34 34 34 34 34 34 34 34 34>,
						<1 32 32 32 32 32 32 32 32 32 32 32 32>,
						<1 30 30 30 30 30 30 30 30 30 30 30 30>,
						<1 127 127 127 127 127 127 127 127 127 127 127 127>;
					};
					b27 {
						channels = <124 124>;
						txs-delta = <0 0 0>;
						rates-ofdm = <34 34 34 34 34 34 34 34>;
						rates-mcs =
						<1 34 34 34 34 34 34 34 34 34 34>,
						<1 31 31 31 31 31 31 31 31 31 31>,
						<1 30 30 30 30 30 30 30 30 30 30>,
						<1 127 127 127 127 127 127 127 127 127 127>;
						rates-ru =
						<1 14 14 14 14 14 14 14 14 14 14 14 14>,
						<1 20 20 20 20 20 20 20 20 20 20 20 20>,
						<1 27 27 27 27 27 27 27 27 27 27 27 27>,
						<1 34 34 34 34 34 34 34 34 34 34 34 34>,
						<1 127 127 127 127 127 127 127 127 127 127 127 127>,
						<1 127 127 127 127 127 127 127 127 127 127 127 127>,
						<1 127 127 127 127 127 127 127 127 127 127 127 127>;
					};
					b28 {
						channels = <126 126>;
						txs-delta = <0 0 0>;
						rates-ofdm = <34 34 34 34 34 34 34 34>;
						rates-mcs =
						<1 34 34 34 34 34 34 34 34 34 34>,
						<1 31 31 31 31 31 31 31 31 31 31>,
						<1 30 30 30 30 30 30 30 30 30 30>,
						<1 127 127 127 127 127 127 127 127 127 127>;
						rates-ru =
						<1 14 14 14 14 14 14 14 14 14 14 14 14>,
						<1 20 20 20 20 20 20 20 20 20 20 20 20>,
						<1 27 27 27 27 27 27 27 27 27 27 27 27>,
						<1 34 34 34 34 34 34 34 34 34 34 34 34>,
						<1 32 32 32 32 32 32 32 32 32 32 32 32>,
						<1 127 127 127 127 127 127 127 127 127 127 127 127>,
						<1 127 127 127 127 127 127 127 127 127 127 127 127>;
					};
					b29 {
						channels = <128 128>;
						txs-delta = <0 0 0>;
						rates-ofdm = <34 34 34 34 34 34 34 34>;
						rates-mcs =
						<1 34 34 34 34 34 34 34 34 34 34>,
						<1 31 31 31 31 31 31 31 31 31 31>,
						<1 30 30 30 30 30 30 30 30 30 30>,
						<1 127 127 127 127 127 127 127 127 127 127>;
						rates-ru =
						<1 14 14 14 14 14 14 14 14 14 14 14 14>,
						<1 20 20 20 20 20 20 20 20 20 20 20 20>,
						<1 27 27 27 27 27 27 27 27 27 27 27 27>,
						<1 34 34 34 34 34 34 34 34 34 34 34 34>,
						<1 127 127 127 127 127 127 127 127 127 127 127 127>,
						<1 127 127 127 127 127 127 127 127 127 127 127 127>,
						<1 127 127 127 127 127 127 127 127 127 127 127 127>;
					};
					b30 {
						channels = <132 132>;
						txs-delta = <0 0 0>;
						rates-ofdm = <34 34 34 34 34 34 34 34>;
						rates-mcs =
						<1 34 34 34 34 34 34 34 34 34 34>,
						<1 31 31 31 31 31 31 31 31 31 31>,
						<1 30 30 30 30 30 30 30 30 30 30>,
						<1 127 127 127 127 127 127 127 127 127 127>;
						rates-ru =
						<1 14 14 14 14 14 14 14 14 14 14 14 14>,
						<1 20 20 20 20 20 20 20 20 20 20 20 20>,
						<1 27 27 27 27 27 27 27 27 27 27 27 27>,
						<1 34 34 34 34 34 34 34 34 34 34 34 34>,
						<1 127 127 127 127 127 127 127 127 127 127 127 127>,
						<1 127 127 127 127 127 127 127 127 127 127 127 127>,
						<1 127 127 127 127 127 127 127 127 127 127 127 127>;
					};
					b31 {
						channels = <134 134>;
						txs-delta = <0 0 0>;
						rates-ofdm = <34 34 34 34 34 34 34 34>;
						rates-mcs =
						<1 34 34 34 34 34 34 34 34 34 34>,
						<1 31 31 31 31 31 31 31 31 31 31>,
						<1 30 30 30 30 30 30 30 30 30 30>,
						<1 127 127 127 127 127 127 127 127 127 127>;
						rates-ru =
						<1 14 14 14 14 14 14 14 14 14 14 14 14>,
						<1 20 20 20 20 20 20 20 20 20 20 20 20>,
						<1 27 27 27 27 27 27 27 27 27 27 27 27>,
						<1 34 34 34 34 34 34 34 34 34 34 34 34>,
						<1 32 32 32 32 32 32 32 32 32 32 32 32>,
						<1 127 127 127 127 127 127 127 127 127 127 127 127>,
						<1 127 127 127 127 127 127 127 127 127 127 127 127>;
					};
					b32 {
						channels = <136 136>;
						txs-delta = <0 0 0>;
						rates-ofdm = <33 33 33 33 33 33 33 33>;
						rates-mcs =
						<1 33 33 33 33 33 33 33 33 33 33>,
						<1 31 31 31 31 31 31 31 31 31 31>,
						<1 30 30 30 30 30 30 30 30 30 30>,
						<1 127 127 127 127 127 127 127 127 127 127>;
						rates-ru =
						<1 14 14 14 14 14 14 14 14 14 14 14 14>,
						<1 20 20 20 20 20 20 20 20 20 20 20 20>,
						<1 27 27 27 27 27 27 27 27 27 27 27 27>,
						<1 34 34 34 34 34 34 34 34 34 34 34 34>,
						<1 127 127 127 127 127 127 127 127 127 127 127 127>,
						<1 127 127 127 127 127 127 127 127 127 127 127 127>,
						<1 127 127 127 127 127 127 127 127 127 127 127 127>;
					};
					b33 {
						channels = <138 138>;
						txs-delta = <0 0 0>;
						rates-ofdm = <33 33 33 33 33 33 33 33>;
						rates-mcs =
						<1 33 33 33 33 33 33 33 33 33 33>,
						<1 31 31 31 31 31 31 31 31 31 31>,
						<1 30 30 30 30 30 30 30 30 30 30>,
						<1 127 127 127 127 127 127 127 127 127 127>;
						rates-ru =
						<1 14 14 14 14 14 14 14 14 14 14 14 14>,
						<1 20 20 20 20 20 20 20 20 20 20 20 20>,
						<1 27 27 27 27 27 27 27 27 27 27 27 27>,
						<1 34 34 34 34 34 34 34 34 34 34 34 34>,
						<1 32 32 32 32 32 32 32 32 32 32 32 32>,
						<1 30 30 30 30 30 30 30 30 30 30 30 30>,
						<1 127 127 127 127 127 127 127 127 127 127 127 127>;
					};
					b34 {
						channels = <140 140>;
						txs-delta = <0 0 0>;
						rates-ofdm = <32 32 32 32 32 32 32 32>;
						rates-mcs =
						<1 31 31 31 31 31 31 31 31 31 31>,
						<1 31 31 31 31 31 31 31 31 31 31>,
						<1 30 30 30 30 30 30 30 30 30 30>,
						<1 127 127 127 127 127 127 127 127 127 127>;
						rates-ru =
						<1 12 12 12 12 12 12 12 12 12 12 12 12>,
						<1 18 18 18 18 18 18 18 18 18 18 18 18>,
						<1 25 25 25 25 25 25 25 25 25 25 25 25>,
						<1 32 32 32 32 32 32 32 32 32 32 32 32>,
						<1 127 127 127 127 127 127 127 127 127 127 127 127>,
						<1 127 127 127 127 127 127 127 127 127 127 127 127>,
						<1 127 127 127 127 127 127 127 127 127 127 127 127>;
					};
					b35 {
						channels = <142 142>;
						txs-delta = <0 0 0>;
						rates-ofdm = <32 32 32 32 32 32 32 32>;
						rates-mcs =
						<1 31 31 31 31 31 31 31 31 31 31>,
						<1 31 31 31 31 31 31 31 31 31 31>,
						<1 30 30 30 30 30 30 30 30 30 30>,
						<1 127 127 127 127 127 127 127 127 127 127>;
						rates-ru =
						<1 12 12 12 12 12 12 12 12 12 12 12 12>,
						<1 18 18 18 18 18 18 18 18 18 18 18 18>,
						<1 25 25 25 25 25 25 25 25 25 25 25 25>,
						<1 32 32 32 32 32 32 32 32 32 32 32 32>,
						<1 32 32 32 32 32 32 32 32 32 32 32 32>,
						<1 127 127 127 127 127 127 127 127 127 127 127 127>,
						<1 127 127 127 127 127 127 127 127 127 127 127 127>;
					};
					b36 {
						channels = <144 144>;
						txs-delta = <0 0 0>;
						rates-ofdm = <34 34 34 34 34 34 34 34>;
						rates-mcs =
						<1 34 34 34 34 34 34 34 34 34 34>,
						<1 31 31 31 31 31 31 31 31 31 31>,
						<1 30 30 30 30 30 30 30 30 30 30>,
						<1 127 127 127 127 127 127 127 127 127 127>;
						rates-ru =
						<1 14 14 14 14 14 14 14 14 14 14 14 14>,
						<1 20 20 20 20 20 20 20 20 20 20 20 20>,
						<1 27 27 27 27 27 27 27 27 27 27 27 27>,
						<1 34 34 34 34 34 34 34 34 34 34 34 34>,
						<1 127 127 127 127 127 127 127 127 127 127 127 127>,
						<1 127 127 127 127 127 127 127 127 127 127 127 127>,
						<1 127 127 127 127 127 127 127 127 127 127 127 127>;
					};
					b37 {
						channels = <149 149>;
						txs-delta = <0 0 0>;
						rates-ofdm = <37 37 37 37 37 37 37 37>;
						rates-mcs =
						<1 34 34 34 34 34 34 34 34 34 34>,
						<1 32 32 32 32 32 32 32 32 32 32>,
						<1 30 30 30 30 30 30 30 30 30 30>,
						<1 127 127 127 127 127 127 127 127 127 127>;
						rates-ru =
						<1 14 14 14 14 14 14 14 14 14 14 14 14>,
						<1 20 20 20 20 20 20 20 20 20 20 20 20>,
						<1 27 27 27 27 27 27 27 27 27 27 27 27>,
						<1 34 34 34 34 34 34 34 34 34 34 34 34>,
						<1 127 127 127 127 127 127 127 127 127 127 127 127>,
						<1 127 127 127 127 127 127 127 127 127 127 127 127>,
						<1 127 127 127 127 127 127 127 127 127 127 127 127>;
					};
					b38 {
						channels = <151 151>;
						txs-delta = <0 0 0>;
						rates-ofdm = <37 37 37 37 37 37 37 37>;
						rates-mcs =
						<1 34 34 34 34 34 34 34 34 34 34>,
						<1 32 32 32 32 32 32 32 32 32 32>,
						<1 30 30 30 30 30 30 30 30 30 30>,
						<1 127 127 127 127 127 127 127 127 127 127>;
						rates-ru =
						<1 14 14 14 14 14 14 14 14 14 14 14 14>,
						<1 20 20 20 20 20 20 20 20 20 20 20 20>,
						<1 27 27 27 27 27 27 27 27 27 27 27 27>,
						<1 34 34 34 34 34 34 34 34 34 34 34 34>,
						<1 32 32 32 32 32 32 32 32 32 32 32 32>,
						<1 127 127 127 127 127 127 127 127 127 127 127 127>,
						<1 127 127 127 127 127 127 127 127 127 127 127 127>;
					};
					b39 {
						channels = <153 153>;
						txs-delta = <0 0 0>;
						rates-ofdm = <37 37 37 37 37 37 37 37>;
						rates-mcs =
						<1 34 34 34 34 34 34 34 34 34 34>,
						<1 32 32 32 32 32 32 32 32 32 32>,
						<1 30 30 30 30 30 30 30 30 30 30>,
						<1 127 127 127 127 127 127 127 127 127 127>;
						rates-ru =
						<1 14 14 14 14 14 14 14 14 14 14 14 14>,
						<1 20 20 20 20 20 20 20 20 20 20 20 20>,
						<1 27 27 27 27 27 27 27 27 27 27 27 27>,
						<1 34 34 34 34 34 34 34 34 34 34 34 34>,
						<1 127 127 127 127 127 127 127 127 127 127 127 127>,
						<1 127 127 127 127 127 127 127 127 127 127 127 127>,
						<1 127 127 127 127 127 127 127 127 127 127 127 127>;
					};
					b40 {
						channels = <155 155>;
						txs-delta = <0 0 0>;
						rates-ofdm = <37 37 37 37 37 37 37 37>;
						rates-mcs =
						<1 34 34 34 34 34 34 34 34 34 34>,
						<1 32 32 32 32 32 32 32 32 32 32>,
						<1 30 30 30 30 30 30 30 30 30 30>,
						<1 127 127 127 127 127 127 127 127 127 127>;
						rates-ru =
						<1 14 14 14 14 14 14 14 14 14 14 14 14>,
						<1 20 20 20 20 20 20 20 20 20 20 20 20>,
						<1 27 27 27 27 27 27 27 27 27 27 27 27>,
						<1 34 34 34 34 34 34 34 34 34 34 34 34>,
						<1 32 32 32 32 32 32 32 32 32 32 32 32>,
						<1 30 30 30 30 30 30 30 30 30 30 30 30>,
						<1 127 127 127 127 127 127 127 127 127 127 127 127>;
					};
					b41 {
						channels = <157 157>;
						txs-delta = <0 0 0>;
						rates-ofdm = <37 37 37 37 37 37 37 37>;
						rates-mcs =
						<1 34 34 34 34 34 34 34 34 34 34>,
						<1 32 32 32 32 32 32 32 32 32 32>,
						<1 30 30 30 30 30 30 30 30 30 30>,
						<1 127 127 127 127 127 127 127 127 127 127>;
						rates-ru =
						<1 14 14 14 14 14 14 14 14 14 14 14 14>,
						<1 20 20 20 20 20 20 20 20 20 20 20 20>,
						<1 27 27 27 27 27 27 27 27 27 27 27 27>,
						<1 34 34 34 34 34 34 34 34 34 34 34 34>,
						<1 127 127 127 127 127 127 127 127 127 127 127 127>,
						<1 127 127 127 127 127 127 127 127 127 127 127 127>,
						<1 127 127 127 127 127 127 127 127 127 127 127 127>;
					};
					b42 {
						channels = <159 159>;
						txs-delta = <0 0 0>;
						rates-ofdm = <37 37 37 37 37 37 37 37>;
						rates-mcs =
						<1 34 34 34 34 34 34 34 34 34 34>,
						<1 32 32 32 32 32 32 32 32 32 32>,
						<1 30 30 30 30 30 30 30 30 30 30>,
						<1 127 127 127 127 127 127 127 127 127 127>;
						rates-ru =
						<1 14 14 14 14 14 14 14 14 14 14 14 14>,
						<1 20 20 20 20 20 20 20 20 20 20 20 20>,
						<1 27 27 27 27 27 27 27 27 27 27 27 27>,
						<1 34 34 34 34 34 34 34 34 34 34 34 34>,
						<1 32 32 32 32 32 32 32 32 32 32 32 32>,
						<1 127 127 127 127 127 127 127 127 127 127 127 127>,
						<1 127 127 127 127 127 127 127 127 127 127 127 127>;
					};
					b43 {
						channels = <161 161>;
						txs-delta = <0 0 0>;
						rates-ofdm = <37 37 37 37 37 37 37 37>;
						rates-mcs =
						<1 34 34 34 34 34 34 34 34 34 34>,
						<1 32 32 32 32 32 32 32 32 32 32>,
						<1 30 30 30 30 30 30 30 30 30 30>,
						<1 127 127 127 127 127 127 127 127 127 127>;
						rates-ru =
						<1 14 14 14 14 14 14 14 14 14 14 14 14>,
						<1 20 20 20 20 20 20 20 20 20 20 20 20>,
						<1 27 27 27 27 27 27 27 27 27 27 27 27>,
						<1 34 34 34 34 34 34 34 34 34 34 34 34>,
						<1 127 127 127 127 127 127 127 127 127 127 127 127>,
						<1 127 127 127 127 127 127 127 127 127 127 127 127>,
						<1 127 127 127 127 127 127 127 127 127 127 127 127>;
					};
					b44 {
						channels = <163 163>;
						txs-delta = <0 0 0>;
						rates-ofdm = <127 127 127 127 127 127 127 127>;
						rates-mcs =
						<4 127 127 127 127 127 127 127 127 127 127>;
						rates-ru =
						<4 127 127 127 127 127 127 127 127 127 127 127 127>,
						<1 32 32 32 32 32 32 32 32 32 32 32 32>,
						<1 30 30 30 30 30 30 30 30 30 30 30 30>,
						<1 127 127 127 127 127 127 127 127 127 127 127 127>;
					};
					b45 {
						channels = <165 165>;
						txs-delta = <0 0 0>;
						rates-ofdm = <37 37 37 37 37 37 37 37>;
						rates-mcs =
						<1 34 34 34 34 34 34 34 34 34 34>,
						<1 32 32 32 32 32 32 32 32 32 32>,
						<1 30 30 30 30 30 30 30 30 30 30>,
						<1 127 127 127 127 127 127 127 127 127 127>;
						rates-ru =
						<1 14 14 14 14 14 14 14 14 14 14 14 14>,
						<1 20 20 20 20 20 20 20 20 20 20 20 20>,
						<1 27 27 27 27 27 27 27 27 27 27 27 27>,
						<1 34 34 34 34 34 34 34 34 34 34 34 34>,
						<1 127 127 127 127 127 127 127 127 127 127 127 127>,
						<1 127 127 127 127 127 127 127 127 127 127 127 127>,
						<1 127 127 127 127 127 127 127 127 127 127 127 127>;
					};
					b46 {
						channels = <167 167>;
						txs-delta = <0 0 0>;
						rates-ofdm = <37 37 37 37 37 37 37 37>;
						rates-mcs =
						<1 34 34 34 34 34 34 34 34 34 34>,
						<1 32 32 32 32 32 32 32 32 32 32>,
						<1 30 30 30 30 30 30 30 30 30 30>,
						<1 127 127 127 127 127 127 127 127 127 127>;
						rates-ru =
						<1 14 14 14 14 14 14 14 14 14 14 14 14>,
						<1 20 20 20 20 20 20 20 20 20 20 20 20>,
						<1 27 27 27 27 27 27 27 27 27 27 27 27>,
						<1 34 34 34 34 34 34 34 34 34 34 34 34>,
						<1 30 30 30 30 30 30 30 30 30 30 30 30>,
						<1 127 127 127 127 127 127 127 127 127 127 127 127>,
						<1 127 127 127 127 127 127 127 127 127 127 127 127>;
					};
					b47 {
						channels = <169 169>;
						txs-delta = <0 0 0>;
						rates-ofdm = <24 24 24 24 24 24 24 24>;
						rates-mcs =
						<1 24 24 24 24 24 24 24 24 24 24>,
						<1 30 30 30 30 30 30 30 30 30 30>,
						<1 35 35 35 35 35 35 35 35 35 35>,
						<1 127 127 127 127 127 127 127 127 127 127>;
						rates-ru =
						<1 4 4 4 4 4 4 4 4 4 4 4 4>,
						<1 10 10 10 10 10 10 10 10 10 10 10 10>,
						<1 17 17 17 17 17 17 17 17 17 17 17 17>,
						<1 24 24 24 24 24 24 24 24 24 24 24 24>,
						<1 127 127 127 127 127 127 127 127 127 127 127 127>,
						<1 127 127 127 127 127 127 127 127 127 127 127 127>,
						<1 127 127 127 127 127 127 127 127 127 127 127 127>;
					};
					b48 {
						channels = <171 171>;
						txs-delta = <0 0 0>;
						rates-ofdm = <24 24 24 24 24 24 24 24>;
						rates-mcs =
						<1 24 24 24 24 24 24 24 24 24 24>,
						<1 30 30 30 30 30 30 30 30 30 30>,
						<1 35 35 35 35 35 35 35 35 35 35>,
						<1 127 127 127 127 127 127 127 127 127 127>;
						rates-ru =
						<1 4 4 4 4 4 4 4 4 4 4 4 4>,
						<1 10 10 10 10 10 10 10 10 10 10 10 10>,
						<1 17 17 17 17 17 17 17 17 17 17 17 17>,
						<1 24 24 24 24 24 24 24 24 24 24 24 24>,
						<1 30 30 30 30 30 30 30 30 30 30 30 30>,
						<1 35 35 35 35 35 35 35 35 35 35 35 35>,
						<1 127 127 127 127 127 127 127 127 127 127 127 127>;
					};
					b49 {
						channels = <173 173>;
						txs-delta = <0 0 0>;
						rates-ofdm = <24 24 24 24 24 24 24 24>;
						rates-mcs =
						<1 24 24 24 24 24 24 24 24 24 24>,
						<1 30 30 30 30 30 30 30 30 30 30>,
						<1 35 35 35 35 35 35 35 35 35 35>,
						<1 127 127 127 127 127 127 127 127 127 127>;
						rates-ru =
						<1 4 4 4 4 4 4 4 4 4 4 4 4>,
						<1 10 10 10 10 10 10 10 10 10 10 10 10>,
						<1 17 17 17 17 17 17 17 17 17 17 17 17>,
						<1 24 24 24 24 24 24 24 24 24 24 24 24>,
						<1 127 127 127 127 127 127 127 127 127 127 127 127>,
						<1 127 127 127 127 127 127 127 127 127 127 127 127>,
						<1 127 127 127 127 127 127 127 127 127 127 127 127>;
					};
					b50 {
						channels = <175 175>;
						txs-delta = <0 0 0>;
						rates-ofdm = <24 24 24 24 24 24 24 24>;
						rates-mcs =
						<1 24 24 24 24 24 24 24 24 24 24>,
						<1 30 30 30 30 30 30 30 30 30 30>,
						<1 35 35 35 35 35 35 35 35 35 35>,
						<1 127 127 127 127 127 127 127 127 127 127>;
						rates-ru =
						<1 4 4 4 4 4 4 4 4 4 4 4 4>,
						<1 10 10 10 10 10 10 10 10 10 10 10 10>,
						<1 17 17 17 17 17 17 17 17 17 17 17 17>,
						<1 24 24 24 24 24 24 24 24 24 24 24 24>,
						<1 30 30 30 30 30 30 30 30 30 30 30 30>,
						<1 127 127 127 127 127 127 127 127 127 127 127 127>,
						<1 127 127 127 127 127 127 127 127 127 127 127 127>;
					};
					b51 {
						channels = <177 177>;
						txs-delta = <0 0 0>;
						rates-ofdm = <24 24 24 24 24 24 24 24>;
						rates-mcs =
						<1 24 24 24 24 24 24 24 24 24 24>,
						<1 30 30 30 30 30 30 30 30 30 30>,
						<1 35 35 35 35 35 35 35 35 35 35>,
						<1 127 127 127 127 127 127 127 127 127 127>;
						rates-ru =
						<1 4 4 4 4 4 4 4 4 4 4 4 4>,
						<1 10 10 10 10 10 10 10 10 10 10 10 10>,
						<1 17 17 17 17 17 17 17 17 17 17 17 17>,
						<1 24 24 24 24 24 24 24 24 24 24 24 24>,
						<1 127 127 127 127 127 127 127 127 127 127 127 127>,
						<1 127 127 127 127 127 127 127 127 127 127 127 127>,
						<1 127 127 127 127 127 127 127 127 127 127 127 127>;
					};
			  };
		};
	};
};
